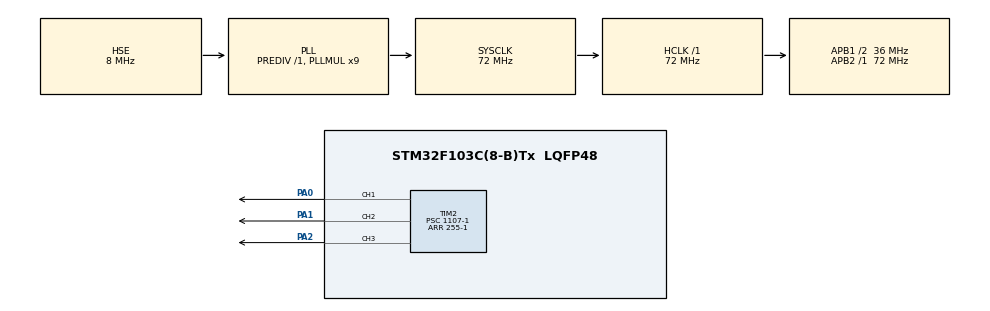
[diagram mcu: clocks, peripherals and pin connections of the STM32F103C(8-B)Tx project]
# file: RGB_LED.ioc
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FREERTOS.Tasks01=defaultTask,24,128,StartDefaultTask,Default,NULL,Dynamic,NULL,NULL;my_RGB_LED_Task,8,128,Start_RGB_LED_Task,Default,NULL,Static,my_RGB_LED_TaskBuffer,my_RGB_LED_TaskControlBlock
Mcu.Family=STM32F1
Mcu.Name=STM32F103C(8-B)Tx
Mcu.Package=LQFP48
NVIC.PriorityGroup=NVIC_PRIORITYGROUP_4
NVIC.TIM4_IRQn=true\:0\:0\:false\:false\:true\:false\:false\:true
NVIC.TimeBase=TIM4_IRQn
NVIC.TimeBaseIP=TIM4
PA0-WKUP.Signal=S_TIM2_CH1_ETR
PA1.Signal=S_TIM2_CH2
PA13.Mode=Trace_Asynchronous_SW
PA13.Signal=SYS_JTMS-SWDIO
PA14.Mode=Trace_Asynchronous_SW
PA14.Signal=SYS_JTCK-SWCLK
PA2.Signal=S_TIM2_CH3
PB3.Mode=Trace_Asynchronous_SW
PB3.Signal=SYS_JTDO-TRACESWO
PD0-OSC_IN.Mode=HSE-External-Oscillator
PD0-OSC_IN.Signal=RCC_OSC_IN
PD1-OSC_OUT.Mode=HSE-External-Oscillator
PD1-OSC_OUT.Signal=RCC_OSC_OUT
ProjectManager.HeapSize=0x200
ProjectManager.StackSize=0x400
ProjectManager.TargetToolchain=STM32CubeIDE
RCC.AHBFreq_Value=72000000
RCC.APB1CLKDivider=RCC_HCLK_DIV2
RCC.APB1Freq_Value=36000000
RCC.APB1TimFreq_Value=72000000
RCC.APB2Freq_Value=72000000
RCC.APB2TimFreq_Value=72000000
RCC.HCLKFreq_Value=72000000
RCC.PLLMUL=RCC_PLL_MUL9
RCC.PLLSourceVirtual=RCC_PLLSOURCE_HSE
RCC.SYSCLKFreq_VALUE=72000000
RCC.SYSCLKSource=RCC_SYSCLKSOURCE_PLLCLK
RCC.USBFreq_Value=72000000
SH.S_TIM2_CH1_ETR.0=TIM2_CH1,PWM Generation1 CH1
SH.S_TIM2_CH2.0=TIM2_CH2,PWM Generation2 CH2
SH.S_TIM2_CH3.0=TIM2_CH3,PWM Generation3 CH3
TIM2.Channel-PWM\ Generation1\ CH1=TIM_CHANNEL_1
TIM2.Channel-PWM\ Generation2\ CH2=TIM_CHANNEL_2
TIM2.Channel-PWM\ Generation3\ CH3=TIM_CHANNEL_3
TIM2.Period=255-1
TIM2.Prescaler=1107-1
VP_FREERTOS_VS_CMSIS_V2.Mode=CMSIS_V2
VP_SYS_VS_tim4.Mode=TIM4
VP_TIM2_VS_ClockSourceINT.Mode=Internal
board=custom

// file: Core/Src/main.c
/* USER CODE BEGIN Header */
/**
 ******************************************************************************
 * @file           : main.c
 * @brief          : Main program body
 ******************************************************************************
 * @attention
 *
 * <h2><center>&copy; Copyright (c) 2021 STMicroelectronics.
 * All rights reserved.</center></h2>
 *
 * This software component is licensed by ST under BSD 3-Clause license,
 * the "License"; You may not use this file except in compliance with the
 * License. You may obtain a copy of the License at:
 *                        opensource.org/licenses/BSD-3-Clause
 *
 ******************************************************************************
 */
/* USER CODE END Header */
#include "main.h"
#include "cmsis_os.h"

typedef StaticTask_t osStaticThreadDef_t;

TIM_HandleTypeDef htim2;

/* Definitions for defaultTask */
osThreadId_t defaultTaskHandle;
const osThreadAttr_t defaultTask_attributes = {
  .name = "defaultTask",
  .priority = (osPriority_t) osPriorityNormal,
  .stack_size = 128 * 4
};
/* Definitions for my_RGB_LED_Task */
osThreadId_t my_RGB_LED_TaskHandle;
uint32_t my_RGB_LED_TaskBuffer[ 128 ];
osStaticThreadDef_t my_RGB_LED_TaskControlBlock;
const osThreadAttr_t my_RGB_LED_Task_attributes = {
  .name = "my_RGB_LED_Task",
  .stack_mem = &my_RGB_LED_TaskBuffer[0],
  .stack_size = sizeof(my_RGB_LED_TaskBuffer),
  .cb_mem = &my_RGB_LED_TaskControlBlock,
  .cb_size = sizeof(my_RGB_LED_TaskControlBlock),
  .priority = (osPriority_t) osPriorityLow,
};

void SystemClock_Config(void);
static void MX_GPIO_Init(void);
static void MX_TIM2_Init(void);
void StartDefaultTask(void *argument);
void Start_RGB_LED_Task(void *argument);

/* USER CODE BEGIN 0 */
// set values to the led
void rgb_set(uint8_t red, uint8_t green, uint8_t blue) {
	htim2.Instance->CCR1 = 255 - red; // ���� RGB � ����� ������� �� htim2.Instance->CCR1 = red;
	htim2.Instance->CCR2 = 255 - green; // ���� RGB � ����� ������� �� htim2.Instance->CCR1 = green;
	htim2.Instance->CCR3 = 255 - blue; // ���� RGB � ����� ������� �� htim2.Instance->CCR1 = blue;
}
/* USER CODE END 0 */

int main(void)
{

  /* MCU Configuration--------------------------------------------------------*/

  /* Reset of all peripherals, Initializes the Flash interface and the Systick. */
  HAL_Init();

  /* Configure the system clock */
  SystemClock_Config();

  /* Initialize all configured peripherals */
  MX_GPIO_Init();
  MX_TIM2_Init();
  /* USER CODE BEGIN 2 */
	HAL_TIM_PWM_Start(&htim2, TIM_CHANNEL_1);
	HAL_TIM_PWM_Start(&htim2, TIM_CHANNEL_2);
	HAL_TIM_PWM_Start(&htim2, TIM_CHANNEL_3);
  /* USER CODE END 2 */

  /* Init scheduler */
  osKernelInitialize();

  /* Create the thread(s) */
  /* creation of defaultTask */
  defaultTaskHandle = osThreadNew(StartDefaultTask, NULL, &defaultTask_attributes);

  /* creation of my_RGB_LED_Task */
  my_RGB_LED_TaskHandle = osThreadNew(Start_RGB_LED_Task, NULL, &my_RGB_LED_Task_attributes);

  /* Start scheduler */
  osKernelStart();

  /* We should never get here as control is now taken by the scheduler */
  /* Infinite loop */
	while (1) {

	}
}

void SystemClock_Config(void)
{
  RCC_OscInitTypeDef RCC_OscInitStruct = {0};
  RCC_ClkInitTypeDef RCC_ClkInitStruct = {0};

  /** Initializes the RCC Oscillators according to the specified parameters
  * in the RCC_OscInitTypeDef structure.
  */
  RCC_OscInitStruct.OscillatorType = RCC_OSCILLATORTYPE_HSE;
  RCC_OscInitStruct.HSEState = RCC_HSE_ON;
  RCC_OscInitStruct.HSEPredivValue = RCC_HSE_PREDIV_DIV1;
  RCC_OscInitStruct.HSIState = RCC_HSI_ON;
  RCC_OscInitStruct.PLL.PLLState = RCC_PLL_ON;
  RCC_OscInitStruct.PLL.PLLSource = RCC_PLLSOURCE_HSE;
  RCC_OscInitStruct.PLL.PLLMUL = RCC_PLL_MUL9;
  if (HAL_RCC_OscConfig(&RCC_OscInitStruct) != HAL_OK)
  {
    Error_Handler();
  }
  /** Initializes the CPU, AHB and APB buses clocks
  */
  RCC_ClkInitStruct.ClockType = RCC_CLOCKTYPE_HCLK|RCC_CLOCKTYPE_SYSCLK
                              |RCC_CLOCKTYPE_PCLK1|RCC_CLOCKTYPE_PCLK2;
  RCC_ClkInitStruct.SYSCLKSource = RCC_SYSCLKSOURCE_PLLCLK;
  RCC_ClkInitStruct.AHBCLKDivider = RCC_SYSCLK_DIV1;
  RCC_ClkInitStruct.APB1CLKDivider = RCC_HCLK_DIV2;
  RCC_ClkInitStruct.APB2CLKDivider = RCC_HCLK_DIV1;

  if (HAL_RCC_ClockConfig(&RCC_ClkInitStruct, FLASH_LATENCY_2) != HAL_OK)
  {
    Error_Handler();
  }
}

static void MX_TIM2_Init(void)
{

  TIM_ClockConfigTypeDef sClockSourceConfig = {0};
  TIM_MasterConfigTypeDef sMasterConfig = {0};
  TIM_OC_InitTypeDef sConfigOC = {0};

  htim2.Instance = TIM2;
  htim2.Init.Prescaler = 1107-1;
  htim2.Init.CounterMode = TIM_COUNTERMODE_UP;
  htim2.Init.Period = 255-1;
  htim2.Init.ClockDivision = TIM_CLOCKDIVISION_DIV1;
  htim2.Init.AutoReloadPreload = TIM_AUTORELOAD_PRELOAD_DISABLE;
  if (HAL_TIM_Base_Init(&htim2) != HAL_OK)
  {
    Error_Handler();
  }
  sClockSourceConfig.ClockSource = TIM_CLOCKSOURCE_INTERNAL;
  if (HAL_TIM_ConfigClockSource(&htim2, &sClockSourceConfig) != HAL_OK)
  {
    Error_Handler();
  }
  if (HAL_TIM_PWM_Init(&htim2) != HAL_OK)
  {
    Error_Handler();
  }
  sMasterConfig.MasterOutputTrigger = TIM_TRGO_RESET;
  sMasterConfig.MasterSlaveMode = TIM_MASTERSLAVEMODE_DISABLE;
  if (HAL_TIMEx_MasterConfigSynchronization(&htim2, &sMasterConfig) != HAL_OK)
  {
    Error_Handler();
  }
  sConfigOC.OCMode = TIM_OCMODE_PWM1;
  sConfigOC.Pulse = 0;
  sConfigOC.OCPolarity = TIM_OCPOLARITY_HIGH;
  sConfigOC.OCFastMode = TIM_OCFAST_DISABLE;
  if (HAL_TIM_PWM_ConfigChannel(&htim2, &sConfigOC, TIM_CHANNEL_1) != HAL_OK)
  {
    Error_Handler();
  }
  if (HAL_TIM_PWM_ConfigChannel(&htim2, &sConfigOC, TIM_CHANNEL_2) != HAL_OK)
  {
    Error_Handler();
  }
  if (HAL_TIM_PWM_ConfigChannel(&htim2, &sConfigOC, TIM_CHANNEL_3) != HAL_OK)
  {
    Error_Handler();
  }
  HAL_TIM_MspPostInit(&htim2);

}

static void MX_GPIO_Init(void)
{

  /* GPIO Ports Clock Enable */
  __HAL_RCC_GPIOD_CLK_ENABLE();
  __HAL_RCC_GPIOA_CLK_ENABLE();
  __HAL_RCC_GPIOB_CLK_ENABLE();

}

void StartDefaultTask(void *argument)
{
	for (;;) {
		osDelay(1);
	}
}

void Start_RGB_LED_Task(void *argument)
{
  /* USER CODE BEGIN Start_RGB_LED_Task */
	/* Infinite loop */
	for (;;) {
		rgb_set(255, 0, 0);   // red only
		osDelay(3000);

		rgb_set(0, 255, 0);   // green only
		osDelay(3000);

		rgb_set(0, 0, 255);   // blue only
		osDelay(3000);

	}
  /* USER CODE END Start_RGB_LED_Task */
}

 /**
  * @brief  Period elapsed callback in non blocking mode
  * @note   This function is called  when TIM4 interrupt took place, inside
  * HAL_TIM_IRQHandler(). It makes a direct call to HAL_IncTick() to increment
  * a global variable "uwTick" used as application time base.
  * @param  htim : TIM handle
  * @retval None
  */
void HAL_TIM_PeriodElapsedCallback(TIM_HandleTypeDef *htim)
{
  if (htim->Instance == TIM4) {
    HAL_IncTick();
  }
}

void Error_Handler(void)
{
	__disable_irq();
	while (1) {
	}
}

/************************ (C) COPYRIGHT STMicroelectronics *****END OF FILE****/
